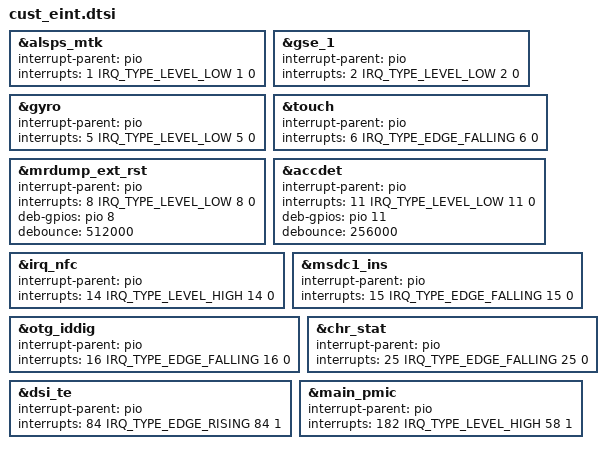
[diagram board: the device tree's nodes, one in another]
/*
 * Generated by MTK SP DrvGen Version: 3.5.160809 for MT6739.
 * 2019-11-11 10:46:44
 * Do Not Modify The File.
 * Copyright Mediatek Inc. (c) 2016.
*/

/*************************
 * EINT DTSI File
*************************/

#include <dt-bindings/interrupt-controller/irq.h>
#include <dt-bindings/interrupt-controller/arm-gic.h>

&alsps_mtk {
	interrupt-parent = <&pio>;
	interrupts = <1 IRQ_TYPE_LEVEL_LOW 1 0>;
	status = "okay";
};

&gse_1 {
	interrupt-parent = <&pio>;
	interrupts = <2 IRQ_TYPE_LEVEL_LOW 2 0>;
	status = "okay";
};

&gyro {
	interrupt-parent = <&pio>;
	interrupts = <5 IRQ_TYPE_LEVEL_LOW 5 0>;
	status = "okay";
};

&touch {
	interrupt-parent = <&pio>;
	interrupts = <6 IRQ_TYPE_EDGE_FALLING 6 0>;
	status = "okay";
};

&mrdump_ext_rst {
	interrupt-parent = <&pio>;
	interrupts = <8 IRQ_TYPE_LEVEL_LOW 8 0>;
	deb-gpios = <&pio 8 0>;
	debounce = <512000>;
	status = "okay";
};

&accdet {
	interrupt-parent = <&pio>;
	interrupts = <11 IRQ_TYPE_LEVEL_LOW 11 0>;
	deb-gpios = <&pio 11 0>;
	debounce = <256000>;
	status = "okay";
};

&irq_nfc {
	interrupt-parent = <&pio>;
	interrupts = <14 IRQ_TYPE_LEVEL_HIGH 14 0>;
	status = "okay";
};

&msdc1_ins {
	interrupt-parent = <&pio>;
	interrupts = <15 IRQ_TYPE_EDGE_FALLING 15 0>;
	status = "okay";
};

&otg_iddig {
	interrupt-parent = <&pio>;
	interrupts = <16 IRQ_TYPE_EDGE_FALLING 16 0>;
	status = "okay";
};

&chr_stat {
	interrupt-parent = <&pio>;
	interrupts = <25 IRQ_TYPE_EDGE_FALLING 25 0>;
	status = "okay";
};

&dsi_te {
	interrupt-parent = <&pio>;
	interrupts = <84 IRQ_TYPE_EDGE_RISING 84 1>;
	status = "okay";
};

&main_pmic {
	interrupt-parent = <&pio>;
	interrupts = <182 IRQ_TYPE_LEVEL_HIGH 58 1>;
	status = "okay";
};

